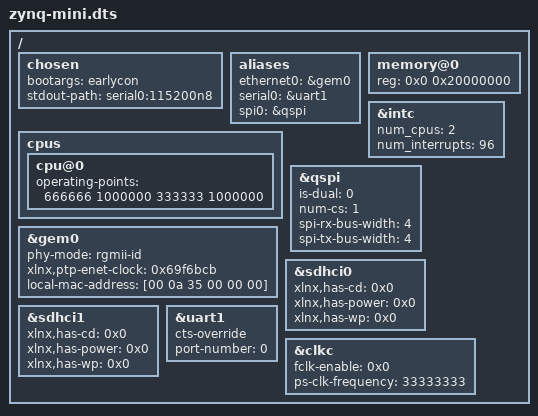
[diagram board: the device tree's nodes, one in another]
/*
 * CAUTION: This file is automatically generated by Xilinx.
 * Version: XSCT 2025.1
 * Today is: Tue Aug  4 12:06:56 2026
 */


/dts-v1/;
#include "zynq-7000.dtsi"
/ {
	chosen {
		bootargs = "earlycon";
		stdout-path = "serial0:115200n8";
	};

	aliases {
		ethernet0 = &gem0;
		serial0 = &uart1;
		spi0 = &qspi;
	};

	memory@0 {
		device_type = "memory";
		reg = <0x0 0x20000000>;
	};

	cpus {
		cpu@0 {
			operating-points = <666666 1000000 333333 1000000>;
		};
	};

	&gem0 {
		phy-mode = "rgmii-id";
		status = "okay";
		xlnx,ptp-enet-clock = <0x69f6bcb>;
		local-mac-address = [00 0a 35 00 00 00];
	};

	&intc {
		num_cpus = <2>;
		num_interrupts = <96>;
	};
	&qspi {
		is-dual = <0>;
		num-cs = <1>;
		spi-rx-bus-width = <4>;
		spi-tx-bus-width = <4>;
		status = "okay";
	};
	&sdhci0 {
		status = "okay";
		xlnx,has-cd = <0x0>;
		xlnx,has-power = <0x0>;
		xlnx,has-wp = <0x0>;
	};
	&sdhci1 {
		status = "okay";
		xlnx,has-cd = <0x0>;
		xlnx,has-power = <0x0>;
		xlnx,has-wp = <0x0>;
	};
	&uart1 {
		cts-override ;
		device_type = "serial";
		port-number = <0>;
		status = "okay";
	};
	&clkc {
		fclk-enable = <0x0>;
		ps-clk-frequency = <33333333>;
	};
};
